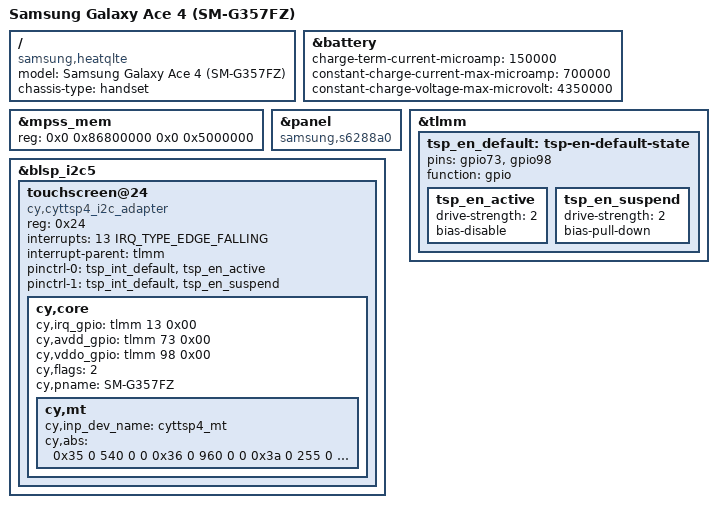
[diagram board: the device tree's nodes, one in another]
// SPDX-License-Identifier: GPL-2.0-only

/dts-v1/;

#include "msm8916-samsung-cprime-common.dtsi"

/*
 * NOTE: The original firmware from Samsung can only boot ARM32 kernels.
 * Unfortunately, the firmware is signed and cannot be replaced easily.
 * There seems to be no way to boot ARM64 kernels on this device at the moment,
 * even though the hardware would support it.
 *
 * However, it is possible to use this device tree by compiling an ARM32 kernel
 * instead. For clarity and build testing this device tree is maintained next
 * to the other MSM8916 device trees. However, it is actually used through
 * arch/arm/boot/dts/qcom-msm8916-samsung-heatqlte.dts
 */

/ {
	model = "Samsung Galaxy Ace 4 (SM-G357FZ)";
	compatible = "samsung,heatqlte", "qcom,msm8916";
	chassis-type = "handset";
};

&battery {
	charge-term-current-microamp = <150000>;
	constant-charge-current-max-microamp = <700000>;
	constant-charge-voltage-max-microvolt = <4350000>;
};

&mpss_mem {
	reg = <0x0 0x86800000 0x0 0x5000000>;
};

&panel {
	compatible = "samsung,s6288a0";
};

&tlmm {
	/delete-node/ tsp-en-default-state;

	tsp_en_default: tsp-en-default-state {
		pins = "gpio73", "gpio98";
		function = "gpio";

		tsp_en_active: tsp_en_active {
			drive-strength = <2>;
			bias-disable;
		};

		tsp_en_suspend: tsp_en_suspend {
			drive-strength = <2>;
			bias-pull-down;
		};
	};
};

&blsp_i2c5 {
        status = "okay";

	touchscreen@24 {
		compatible = "cy,cyttsp4_i2c_adapter";
		reg = <0x24>;
		interrupts = <13 IRQ_TYPE_EDGE_FALLING>;
		interrupt-parent = <&tlmm>;

		pinctrl-names = "pmx_ts_active", "pmx_ts_suspend";
		pinctrl-0 = <&tsp_int_default &tsp_en_active>;
		pinctrl-1 = <&tsp_int_default &tsp_en_suspend>;

		cy,core {
			cy,irq_gpio = <&tlmm 13 0x00>;
			cy,avdd_gpio = <&tlmm 73 0x00>;
			cy,vddo_gpio = <&tlmm 98 0x00>;

			/* CY_CORE_FLAG_POWEROFF_ON_SLEEP */
			cy,flags = <2>;
			cy,pname = "SM-G357FZ";

			cy,mt {
				cy,inp_dev_name = "cyttsp4_mt";
				cy,abs =
					/* ABS_MT_POSITION_X, CY_ABS_MIN_X, CY_ABS_MAX_X, 0, 0 */
					<0x35 0 540 0 0
					/* ABS_MT_POSITION_Y, CY_ABS_MIN_Y, CY_ABS_MAX_Y, 0, 0 */
					 0x36 0 960 0 0
					/* ABS_MT_PRESSURE, CY_ABS_MIN_P, CY_ABS_MAX_P, 0, 0 */
					 0x3a 0 255 0 0
					/* CY_IGNORE_VALUE, CY_ABS_MIN_W, CY_ABS_MAX_W, 0, 0 */
					 0xffff 0 255 0 0
					/* ABS_MT_TRACKING_ID, CY_ABS_MIN_T, CY_ABS_MAX_T, 0, 0 */
					 0x39 0 15 0 0
					/* ABS_MT_TOUCH_MAJOR, 0, 255, 0, 0 */
					 0x30 0 255 0 0
					/* ABS_MT_TOUCH_MINOR, 0, 255, 0, 0 */
					 0x31 0 255 0 0
					/* ABS_MT_ORIENTATION, -128, 127, 0, 0 */
					 0x34 0xfffffed7 127 0 0>;
			};
		};
	};
};
